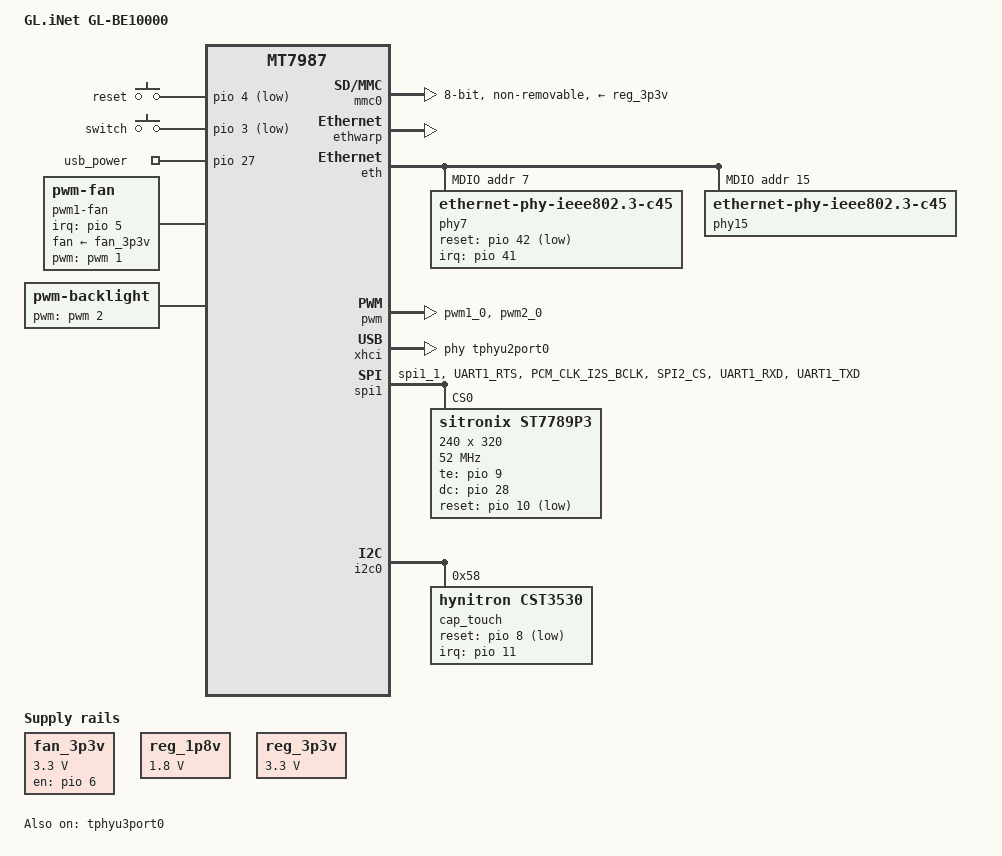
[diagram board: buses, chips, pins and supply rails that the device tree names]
/* SPDX-License-Identifier: (GPL-2.0 OR MIT) */

/dts-v1/;
#include "mt7987a.dtsi"
#include <dt-bindings/interrupt-controller/irq.h>
#include <dt-bindings/interrupt-controller/arm-gic.h>
#include <dt-bindings/phy/phy.h>
#include <dt-bindings/reset/ti-syscon.h>
#include <dt-bindings/clock/mediatek,mt7987-clk.h>
#include <dt-bindings/pinctrl/mt65xx.h>
#include <dt-bindings/input/input.h>

/ {
	model = "GL.iNet GL-BE10000";
	compatible = "glinet,gl-be10000-emmc",
		     "mediatek,mt7987a", "mediatek,mt7987";

	chosen {
		bootargs = "console=ttyS0,115200n1 loglevel=8  \
			    earlycon=uart8250,mmio32,0x11000000 \
                            root=PARTLABEL=rootfs rootwait \
			    rootfstype=squashfs,f2fs pci=pcie_bus_perf";
	};

	gpio-keys {
		compatible = "gpio-keys";

		reset {
			label = "reset";
			linux,code = <KEY_RESTART>;
			gpios = <&pio 4 GPIO_ACTIVE_LOW>;
			debounce-interval = <10>;
		};

		switch {
			label = "switch";
			linux,code = <KEY_SETUP>;
			gpios = <&pio 3 GPIO_ACTIVE_LOW>;
			debounce-interval = <10>;
		};
	};

	gl-hw {
		compatible = "gl-hw-info";
		model = "be10000";
		wan = "eth0";
		lan = "eth1";
		secondwan = "eth1";
		usb-port = "1-1,2-1";
		usb3-bus-dev = "2-1";
		usb-power-require = "9V3A";
		screen = "/dev/fb0,/dev/input/event0";
		fan = "hwmon0 cooling_device0";
		flash_size = <8192>;
		temperature = "/sys/devices/virtual/thermal/thermal_zone0/temp";
		switch-button = "gpio-465";
		reset-button = "gpio-466";
		radio = "mt798711 mt798712";
		lcd_sched = "true";
		dfs;
		noled = "true";
                cfg-partition = "/dev/mmcblk0p5";
		factory_data {
			device_mac = "/dev/mmcblk0p2", "0x4000";
			device_ddns = "/dev/mmcblk0p2", "0x4010";
			device_sn_bak = "/dev/mmcblk0p2", "0x4020";
			device_sn = "/dev/mmcblk0p2", "0x4030";
			country_code = "/dev/mmcblk0p2", "0x4088";
			device_cert = "/dev/mmcblk0p2", "0x5000";
		};
	};


	gpio-export {
		compatible = "gpio-export";

		usb_power {
			gpio-export,name = "usb_power";
			gpio-export,output = <0>;
			gpios = <&pio 27 GPIO_ACTIVE_HIGH>;
		};
	};

	fan_3p3v: regulator-fan-3p3v {
		compatible = "regulator-fixed";
		regulator-name = "fan";
		regulator-min-microvolt = <3300000>;
		regulator-max-microvolt = <3300000>;
		gpio = <&pio 6 GPIO_ACTIVE_HIGH>;
		enable-active-high;
	};

	pwm1-fan {
		compatible = "pwm-fan";
		#cooling-cells = <2>;
		pwms = <&pwm 1 50000 0>;
		fan-supply = <&fan_3p3v>;
		interrupt-parent = <&pio>;
		interrupts = <5 IRQ_TYPE_EDGE_RISING>;
		cooling-levels = <0 36 36 36 36 36 36 36 36 36 36 36 36 36 36 36 36 36 36 36
				36 36 36 36 36 36 36 36 36 36 36 36 36 36 36 36 36 37 38 39
				40 41 42 43 44 45 46 47 48 49 50 51 52 53 54 55 56 57 58 59
				60 61 62 63 64 65 66 67 68 69 70 71 72 73 74 75 76 77 78 79
				80 81 82 83 84 85 86 87 88 89 90 91 92 93 94 95 96 97 98 99
				100 101 102 103 104 105 106 107 108 109 110 111 112 113 114 115 116 117 118 119
				120 121 122 123 124 125 126 127 128 129 130 131 132 133 134 135 136 137 138 139
				140 141 142 143 144 145 146 147 148 149 150 151 152 153 154 155 156 157 158 159
				160 161 162 163 164 165 166 167 168 169 170 171 172 173 174 175 176 177 178 179
				180 181 182 183 184 185 186 187 188 189 190 191 192 193 194 195 196 197 198 199
				200 201 202 203 204 205 206 207 208 209 210 211 212 213 214 215 216 217 218 219
				220 221 222 223 224 225 226 227 228 229 230 231 232 233 234 235 236 237 238 239
				240 241 242 243 244 245 246 247 248 249 250 251 252 253 254 255>;
	};

	backlight {
		compatible = "pwm-backlight";
		pwms = <&pwm 2 50000 0>;
		brightness-levels = <0    1    1    1    2    2    3    4    5    6    7
				8    9   10   12   13   15   16   18   20   22
				24   26   29   31   34   37   40   43   46   50
				53   57   61   65   69   74   78   83   88   93
				98  103  109  114  120  126  132  138  145  151
				158  165  172  179  187  194  202  210  218  226
				235  243  252  261  270  279  289  298  308  318
				328  338  349  359  370  381  392  403  415  426
				438  450  462  474  487  499  512  525  538  551
				565  578  592  606  620  634  649  663  678  693
				708  723  738  754  770  785  801  818  834  850
				867  884  901  918  935  952  970  988 1006 1023
				>;
		default-brightness-level = <95>;
	};

    reg_1p8v: regulator-1p8v {
		compatible = "regulator-fixed";
		regulator-name = "fixed-1.8V";
		regulator-min-microvolt = <1800000>;
		regulator-max-microvolt = <1800000>;
		regulator-boot-on;
		regulator-always-on;
	};

	reg_3p3v: regulator-3p3v {
		compatible = "regulator-fixed";
		regulator-name = "fixed-3.3V";
		regulator-min-microvolt = <3300000>;
		regulator-max-microvolt = <3300000>;
		regulator-boot-on;
		regulator-always-on;
	};
};

&mmc0 {
	pinctrl-names = "default", "state_uhs";
	pinctrl-0 = <&mmc_pins_default>;
	pinctrl-1 = <&mmc_pins_uhs>;
	bus-width = <8>;
	max-frequency = <26000000>;
	assigned-clocks = <&apmixedsys CK_APMIXED_MSDCPLL>;
	assigned-clock-rates = <416000000>;
	cap-mmc-highspeed;
	mmc-ddr-3_3v;
	vqmmc-supply = <&reg_3p3v>;
	vmmc-supply = <&reg_3p3v>;
	non-removable;
	no-sd;
	no-sdio;
	status = "okay";
};

&netsys {
	ethwarp: syscon@15031000 {
		compatible = "mediatek,mt7988-ethwarp", "syscon";
		reg = <0 0x15031000 0 0x1000>;
		#clock-cells = <1>;
	};

	eth: ethernet@15100000 {
		compatible = "mediatek,mt7987-eth";
		reg = <0 0x15100000 0 0x80000>,
		      <0 0x15400000 0 0x20000>;
		interrupts = <GIC_SPI 189 IRQ_TYPE_LEVEL_HIGH>,
				<GIC_SPI 190 IRQ_TYPE_LEVEL_HIGH>,
				<GIC_SPI 191 IRQ_TYPE_LEVEL_HIGH>,
				<GIC_SPI 192 IRQ_TYPE_LEVEL_HIGH>,
				<GIC_SPI 196 IRQ_TYPE_LEVEL_HIGH>,
				<GIC_SPI 197 IRQ_TYPE_LEVEL_HIGH>,
				<GIC_SPI 198 IRQ_TYPE_LEVEL_HIGH>,
				<GIC_SPI 199 IRQ_TYPE_LEVEL_HIGH>;
		clocks = <&ethsys CK_ETHDMA_FE_EN>,
			 <&ethsys CK_ETHDMA_GP2_EN>,
			 <&ethsys CK_ETHDMA_GP1_EN>,
			 <&ethsys CK_ETHDMA_GP3_EN>,
			 <&sgmiisys0 CK_SGM0_TX_EN>,
			 <&sgmiisys0 CK_SGM0_RX_EN>,
			 <&sgmiisys1 CK_SGM1_TX_EN>,
			 <&sgmiisys1 CK_SGM1_RX_EN>,
			 <&topckgen CK_TOP_SGM_0_SEL>,
			 <&topckgen CK_TOP_SGM_1_SEL>,
			 <&topckgen CK_TOP_ETH_GMII_SEL>,
			 <&topckgen CK_TOP_ETH_REFCK_50M_SEL>,
			 <&topckgen CK_TOP_ETH_SYS_200M_SEL>,
			 <&topckgen CK_TOP_ETH_SYS_SEL>,
			 <&topckgen CK_TOP_ETH_XGMII_SEL>,
			 <&topckgen CK_TOP_ETH_MII_SEL>,
			 <&topckgen CK_TOP_NETSYS_SEL>,
			 <&topckgen CK_TOP_NETSYS_500M_SEL>,
			 <&topckgen CK_TOP_NETSYS_2X_SEL>;
		clock-names = "fe", "gp2", "gp1", "gp3", "sgmii_tx250m",
				"sgmii_rx250m", "sgmii2_tx250m", "sgmii2_rx250m",
				"top_sgm0_sel", "top_sgm1_sel", "top_eth_gmii_sel",
				"top_eth_refck_50m_sel", "top_eth_sys_200m_sel",
				"top_eth_sys_sel", "top_eth_xgmii_sel",
				"top_eth_mii_sel", "top_netsys_sel",
				"top_netsys_500m_sel", "top_netsys_pao_2x_sel";
		assigned-clocks = <&topckgen CK_TOP_NETSYS_2X_SEL>,
				  <&topckgen CK_TOP_SGM_0_SEL>,
				  <&topckgen CK_TOP_SGM_1_SEL>;
		assigned-clock-parents = <&apmixedsys CK_APMIXED_NET2PLL>,
					 <&apmixedsys CK_APMIXED_SGMPLL>,
					 <&apmixedsys CK_APMIXED_SGMPLL>;
		mediatek,ethsys = <&ethsys>;
		mediatek,sgmiisys = <&sgmiisys0>, <&sgmiisys1>;
		mediatek,infracfg = <&topmisc>;
		mediatek,toprgu = <&watchdog>;
		pinctrl-names = "default";
		pinctrl-0 = <&mdio0_pins>;
		#reset-cells = <1>;
		#address-cells = <1>;
		#size-cells = <0>;
		status = "okay";

		gmac0: mac@0 {
			compatible = "mediatek,eth-mac";
			reg = <0>;
			phy-mode = "2500base-x";
			phy-handle = <&phy7>;
		};

		gmac1: mac@1 {
			compatible = "mediatek,eth-mac";
			reg = <1>;
			mac-type = "xgdm";
			phy-mode = "internal";
			phy-handle = <&phy15>;
		};

		mdio: mdio-bus {
			#address-cells = <1>;
			#size-cells = <0>;
			reset-gpios = <&pio 0 1>;
			reset-delay-us = <10000>;

			phy7: phy@7 {
				compatible = "ethernet-phy-ieee802.3-c45";
				reg = <7>;
				reset-assert-us = <100000>;
				reset-deassert-us = <100000>;
				reset-gpios = <&pio 42 GPIO_ACTIVE_LOW>;
				interrupt-parent = <&pio>;
				interrupts = <41 IRQ_TYPE_LEVEL_LOW>;
				//realtek,aldps-enable;
			};

			phy15: phy@15 {
				pinctrl-names = "i2p5gbe-led";
				pinctrl-0 = <&i2p5gbe_led0_pins>;
				compatible = "ethernet-phy-ieee802.3-c45";
				interrupt-parent = <&gic>;
				reg = <15>;
				phy-mode = "internal";
			};
		};
	};

	hnat: hnat@15000000 {
		compatible = "mediatek,mtk-hnat_v5";
		reg = <0 0x15100000 0 0x80000>;
		interrupts = <GIC_SPI 198 IRQ_TYPE_LEVEL_HIGH>;
		resets = <&ethsys 0>;
		reset-names = "mtketh";
		mtketh-wan = "eth0";
		mtketh-lan = "eth1";
		mtketh-lan2 = "none";
		mtketh-ppd = "eth1";
		mtketh-max-gmac = <2>;
		mtketh-ppe-num = <2>;
		status = "okay";
	};

	crypto: crypto@15600000 {
		compatible = "inside-secure,safexcel-eip197b",
			     "security-ip-197-srv";
		reg = <0 0x15600000 0 0x180000>;
		interrupts = <GIC_SPI 214 IRQ_TYPE_LEVEL_HIGH>,
				<GIC_SPI 215 IRQ_TYPE_LEVEL_HIGH>,
				<GIC_SPI 216 IRQ_TYPE_LEVEL_HIGH>,
				<GIC_SPI 217 IRQ_TYPE_LEVEL_HIGH>;
		interrupt-names = "ring0", "ring1", "ring2", "ring3";
		eth = <&eth>;
		status = "okay";
	};
};

&afe {
	status = "disabled";
};

&pio {
	spi1_1_pins: spi1_1-pins {
		mux {
			function = "spi";
			groups = "spi1_1";
		};

                conf-pu {
                        pins = "UART1_RTS", "PCM_CLK_I2S_BCLK", "SPI2_CS";
                        drive-strength = <MTK_DRIVE_8mA>;
                        bias-pull-up = <MTK_PUPD_SET_R1R0_11>;
                };

                conf-pd {
                        pins = "UART1_RXD", "UART1_TXD";
                        drive-strength = <MTK_DRIVE_8mA>;
                        bias-pull-down = <MTK_PUPD_SET_R1R0_11>;
                };
	};

	pwm1_pin: pwm1-pin {
		mux {
			function = "pwm";
			groups = "pwm1_0";
		};
	};

	pwm2_pin: pwm2-pin {
		mux {
			function = "pwm";
			groups = "pwm2_0";
		};
	};
};

&pwm {
	pinctrl-names = "default";
	pinctrl-0 = <&pwm1_pin &pwm2_pin>;
	status = "okay";
};

&fan {
	status = "disabled";
};

&tphyu3port0 {
	status = "okay";
};

&xhci {
	mediatek,u3p-dis-msk=<0>;

	phys = <&tphyu2port0 PHY_TYPE_USB2>,
		<&tphyu3port0 PHY_TYPE_USB3>;
};

&spi1 {
	pinctrl-0 = <&spi1_1_pins>;
	pinctrl-names = "default";
	status = "okay";
	cs_setup_time = <2>;

	st7789p3@0 {
		compatible = "sitronix,st7789p3";
		reg = <0>;
		buswidth = <0x8>;
		width = <240>;
		height = <320>;
		rotate = <0>;
		fps = <40>;

		te-gpios = <&pio 9 GPIO_ACTIVE_HIGH>;
		dc-gpios = <&pio 28 GPIO_ACTIVE_HIGH>;
		reset-gpios = <&pio 10 GPIO_ACTIVE_LOW>;
		spi-max-frequency = <52000000>;
	};
};

&i2c0 {
	cap_touch@58 {
		compatible = "hynitron,cst3530";
		reg = <0x58>;
		reset-gpio = <&pio 8 GPIO_ACTIVE_LOW>;
		interrupt-parent = <&pio>;
		interrupts = <11 IRQ_TYPE_EDGE_FALLING>;
		status = "ok";
	};
};
